# A31T21x register map
Vendor: ABOV Semiconductor Co., Ltd.; Series: A31T21x; File version: 1.0
CPU: CM0PLUS r0p1, little endian, no MPU, no FPU, VTOR, 2 interrupt priority bits
Registers are 32-bit, read-write, reset 0x0 unless marked. A register's access mark holds for its fields unless they carry their own. Offsets are from the block's base; [hi:lo] are bit positions; {n}, {i} and the like mark numbered series.

## LED — LED DRIVER/CONTROLLER
Base 0x40006000
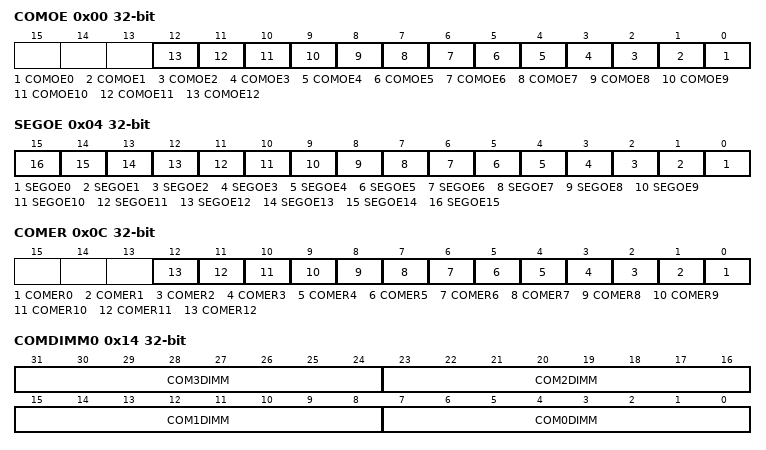
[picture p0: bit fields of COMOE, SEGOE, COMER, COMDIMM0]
0x00 COMOE — COM Output Enable Register
  [n] COMOE{n} (n=0..12) — COMn Output Enable
0x04 SEGOE — SEG Output Enable Register
  [n] SEGOE{n} (n=0..15) — SEGn Output Enable
0x08 PRESD — LED Prescaler Data Register
  [7:0] PRESD — Pre-scale value of LED clock LED Clock = fCLK/(PRESD + 1) (fCLK is a selected input clock)
0x0C COMER — COM Enable Register
  [n] COMER{n} (n=0..12) — Select COM or SEG Enable.
0x10 COMPWID — COM Pulse Width Control Register
  [7:0] COMPWID — COM Pulse Width Control bits COM Width= LED CLK/(COMPWID + 1) (LED CLK is Prescaler output clock)
0x14 COMDIMM0 — LED COM Dimming 0 Register
  [8n+7:8n] COM{n}DIMM (n=0..3) — Dimming Control for COM{n}
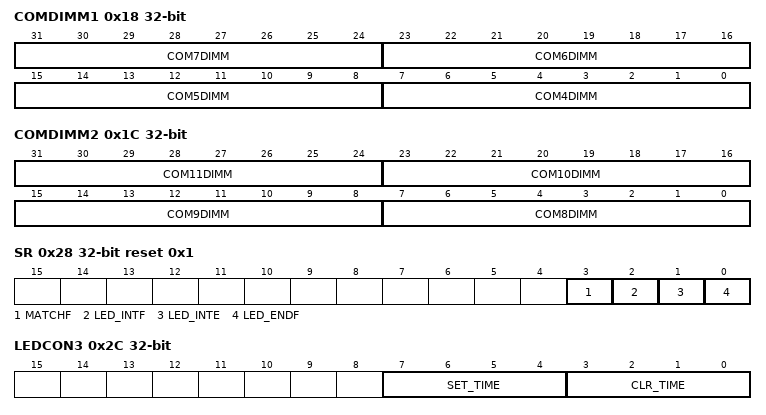
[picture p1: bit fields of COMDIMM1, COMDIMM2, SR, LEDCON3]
0x18 COMDIMM1 — LED COM Dimming 1 Register
  [8n-25:8n-32] COM{n}DIMM (n=4..7) — Dimming Control for COM{n}
0x1C COMDIMM2 — LED COM Dimming 2 Register
  [8n-57:8n-64] COM{n}DIMM (n=8..11) — Dimming Control for COM{n}
0x20 COMDIMM3 — LED COM Dimming 3 Register
  [7:0] COM12DIMM — Dimming Control for COM12
0x24 LEDPD — LED Period Data Register
  [19:0] LEDPD — LED Period. Determine interval between COMx on-time
0x28 SR reset 0x1 — LED STATUS Register
  [3] MATCHF — LED stop counter match flag
  [2] LED_INTF — LED Interrupt Flag(in LED_INTE=1)
  [1] LED_INTE — LED Interrupt Enable
  [0] LED_ENDF — LED Operation End Flag
0x2C LEDCON3 — LED Control 3 Register
  [7:4] SET_TIME — SEG GND start timing
  [3:0] CLR_TIME — SET GND clear timing
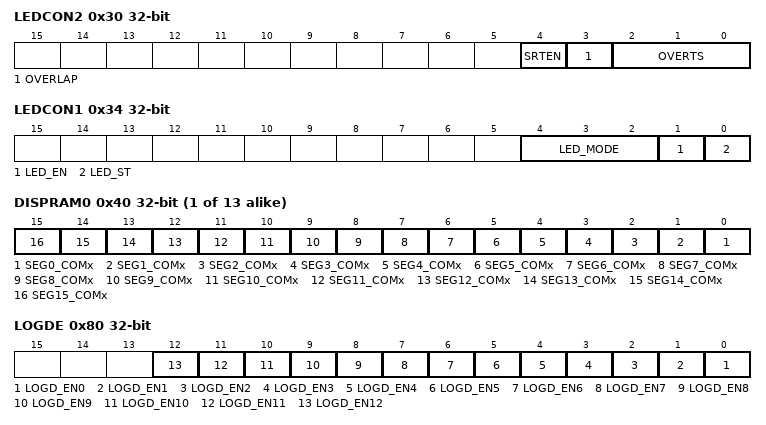
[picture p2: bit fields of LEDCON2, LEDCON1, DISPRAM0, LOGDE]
0x30 LEDCON2 — LED Control 2 Register
  [4] SRTEN — SEG-GND function enable
  [3] OVERLAP — Overlap time configuration
  [2:0] OVERTS — Overlap time selection
0x34 LEDCON1 — LED Control 1 Register
  [4:2] LED_MODE — LED operation mode selection
  [1] LED_EN — LED Enable
  [0] LED_ST — LED Start or Stop under LEDEN=1 condition
{0x40+4i} DISPRAM{i} (i=0..12) — LED Display RAM
  [n] SEG{n}_COMx (n=0..15) — SEG{n}-COMx LED lane display value
0x80 LOGDE — LED Log-scale Dimming Enable Register
  [n] LOGD_EN{n} (n=0..12) — Enable COMx log-scale dimming
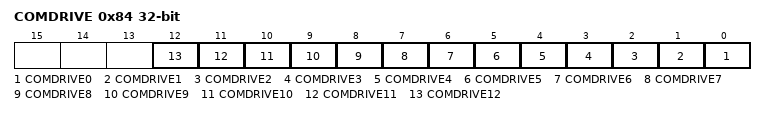
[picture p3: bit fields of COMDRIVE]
0x84 COMDRIVE — LED COM additional driving Register
  [n] COMDRIVE{n} (n=0..12) — Enable COMx additional NMOS driver
0x88 PORTCTRL — LED Port Control Register
  [15:0] PORTx_DIR — Select LED Port Status(0: Floating / 1: Output)
0x8C DLYCNT — LED run signal Delay Count Register
  [7:0] DLYCNT — Delay time before LED_PORTCTRL

## LCD — LCD DRIVER/CONTROLLER
Base 0x40005000
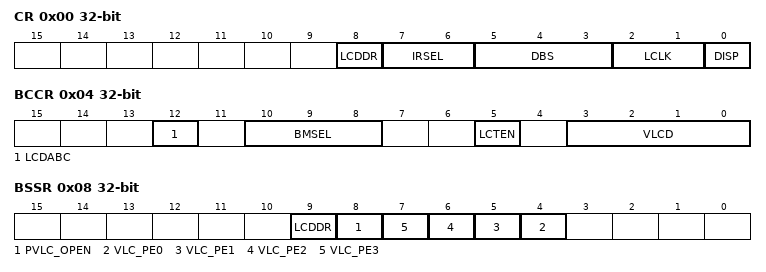
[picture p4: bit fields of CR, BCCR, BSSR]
0x00 CR (reset mask 0xFF) — LCD Driver Control Register
  [8] LCDDR — LCD Driving Resistor for Bias Select
    0=INTERNAL_RESISTORS (Internal LCD driving resistors for bias); 1=EXTERNAL_RESISTORS (External LCD driving resistors for bias)
  [7:6] IRSEL — Internal LCD Bias Dividing Resistor Selection bits
    0=RLCD3 (RLCD3: 105/105/80[kohm] @(1/2)/(1/3)/(1/4) bias); 1=RLCD1 (RLCD1: 10/10/10[kohm] @(1/2)/(1/3)/(1/4) bias); 2=RLCD2 (RLCD2: 66/66/50[kohm] @(1/2)/(1/3)/(1/4) bias); 3=RLCD4 (RLCD4: 320/320/240[kohm] @(1/2)/(1/3)/(1/4) bias)
  [5:3] DBS — LCD Duty and Bias Selection bits
    0=DUTY8_BIAS4 (1/8 duty, 1/4 bias); 1=DUTY6_BIAS4 (1/6 duty, 1/4 bias); 2=DUTY5_BIAS3 (1/5 duty, 1/3 bias); 3=DUTY4_BIAS3 (1/4 duty, 1/3 bias); 4=DUTY3_BIAS3 (1/3 duty, 1/3 bias); 5=DUTY3_BIAS2 (1/3 duty, 1/2 bias)
  [2:1] LCLK — LCD Clock Selection bits (When fLCD = 32.768kHz)
    0=fLCD_128Hz (128Hz); 1=fLCD_256Hz (256Hz); 2=fLCD_512Hz (512Hz); 3=fLCD_1024Hz (1024Hz)
  [0] DISP — LCD Display Control bit
    0=DISPLAY_OFF; 1=DISPLAY_ON (Normal display on)
0x04 BCCR — LCD Automatic Bias and Contrast Control Register. Notes: 1. The above LCD contrast step is based on 1/3 bias with 66kohm RLCD and on 1/4 bias with 50kohm RLCD 2. The "LCD driver contrast control" is disabled during the LCDABC bit (LCD automatic bias) is set to "1b".
  [12] LCDABC — LCD Automatic Bias Control bit
    0=LCD_AUTO_BIAS_OFF (LCD automatic bias is off); 1=LCD_AUTO_BIAS_ON (LCD automatic bias is on)
  [10:8] BMSEL — "Bias Mode A" fsTime Selection bits
    {v}="Bias Mode A" for {v+1}-clock of fLCD (v=0..7)
  [5] LCTEN — LCD Driver Contrast Control bit
    0=Disable LCD driver contrast; 1=Enable LCD driver contrast
  [3:0] VLCD — VLC0 Voltage Control when the contrast is enabled
    0=VDD x 16/31 step; 1=VDD x 16/30 step; 2=VDD x 16/29 step; 3=VDD x 16/28 step; 4=VDD x 16/27 step; 5=VDD x 16/26 step; 6=VDD x 16/25 step; 7=VDD x 16/24 step; 8=VDD x 16/23 step; 9=VDD x 16/22 step; 10=VDD x 16/21 step; 11=VDD x 16/20 step; 12=VDD x 16/19 step; 13=VDD x 16/18 step; 14=VDD x 16/17 step; 15=VDD x 16/16 step
0x08 BSSR — LCD source selection register
  [9] LCDDR — LCD external bias path enable bit
  [8] PVLC_OPEN — LCD external bias path enable bit
  [n+4] VLC_PE{n} (n=0..3) — External bias VLC{n} enable bit
{0x10+i} DR{i} 8-bit (i=0..31) — LCD Display Data Register {i}

## CRC — CYCLIC REDUNDANCY CHECK AND CHECKSUM
Base 0x40000300
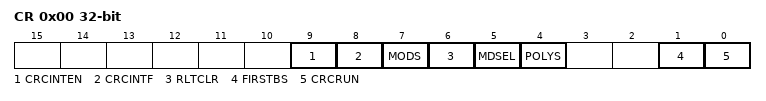
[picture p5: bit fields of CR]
0x00 CR — CRC/Checksum Control Register. Notes: 1. The CRCRLT register and the CRC/Checksum block should be initialized by writing "1b" to the RLTCLR bit before a new CRC/Checksum calculation. 2. The CRCRUN bit should be set to "1b" last time after setting appropriate values to the registers. 3. On the user mode, it will be calculated every writing data to the CRCIN register during CRCRUN==1. 4. On the user mode with SARINC==0, the block is finished by writing "0b" to the CRCRUN bit. 4. It is prohibited writing any data to the CRCIN register during CRCRUN==0. 5. The checksum is calculated by byte unit. Ex) On 0x34A7E991, CRCRLT = 0x34 + 0xA7 + 0xE9 + 0x91.
  [9] CRCINTEN — CRC interrupt enable bit
  [8] CRCINTF — CRC interrupt flag bit
  [7] MODS — User/Auto Mode Selection bit
  [6] RLTCLR — CRC/Checksum Result Data Register (CRCRLT) Initialization bit
  [5] MDSEL — CRC/Checksum Selection bit
  [4] POLYS — Polynomial Selection bit (CRC only)
  [1] FIRSTBS — First Shifted-in Selection bit (CRC only)
  [0] CRCRUN — CRC/Checksum Start Control and Busy bit
0x04 IN — CRC/Checksum Input Data Register
  [31:0] INDATA — CRC Input Data bit
0x08 RLT ro reset 0xFFFF — CRC/Checksum Result Data Register
  [15:0] RLTDATA rw — CRC Result Data bit
0x0C INIT — CRC/Checksum Initial Data Register
  [15:0] INIDATA — CRC Initial Data bit

## TSENSE — Temp Sensor
Base 0x40006300
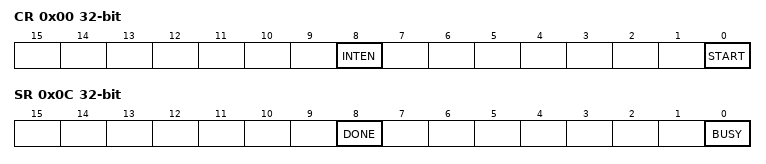
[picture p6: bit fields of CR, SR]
0x00 CR — Temp sensor control register
  [8] INTEN — Temp sensor interrupt enable
  [0] START — Start reference clock counting
0x04 RCCNT — Temp sensor reference clock counter register
  [31:0] RCCV — Reference clock counter initial value
0x08 SCCNT ro — Temp sensor sensing clock counter register
  [31:0] SCCV — Temp sensor counter value
0x0C SR — Temp sensor status register
  [8] DONE — Reference clock counting is running
  [0] BUSY ro — The status of the reference clock counter
